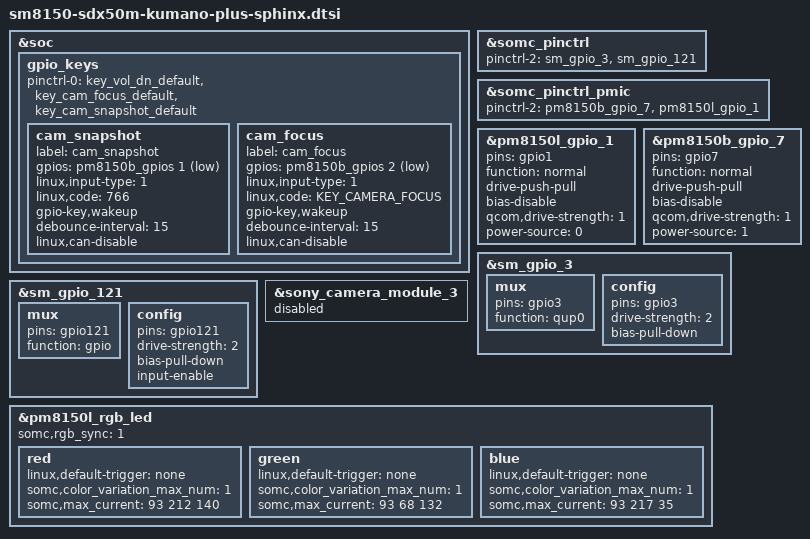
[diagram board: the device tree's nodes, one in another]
/* arch/arm64/boot/dts/somc/sm8150-sdx50m-kumano-plus-sphinx.dtsi
 *
 * This program is free software; you can redistribute it and/or modify
 * it under the terms of the GNU General Public License version 2 and
 * only version 2 as published by the Free Software Foundation.
 *
 * This program is distributed in the hope that it will be useful,
 * but WITHOUT ANY WARRANTY; without even the implied warranty of
 * MERCHANTABILITY or FITNESS FOR A PARTICULAR PURPOSE.  See the
 * GNU General Public License for more details.
 */

#include "sm8150-sdx50m-kumano-plus-common.dtsi"

&soc {
	gpio_keys {
		pinctrl-0 = <&key_vol_dn_default
			     &key_cam_focus_default
			     &key_cam_snapshot_default>;

		cam_snapshot {
			label = "cam_snapshot";
			gpios = <&pm8150b_gpios 1 GPIO_ACTIVE_LOW>;
			linux,input-type = <1>;
			linux,code = <766>;
			gpio-key,wakeup;
			debounce-interval = <15>;
			linux,can-disable;
		};

		cam_focus {
			label = "cam_focus";
			gpios = <&pm8150b_gpios 2 GPIO_ACTIVE_LOW>;
			linux,input-type = <1>;
			linux,code = <KEY_CAMERA_FOCUS>;
			gpio-key,wakeup;
			debounce-interval = <15>;
			linux,can-disable;
		};
	};
};

&somc_pinctrl {
	/* If variant specific default setting is needed,
	fill pinctrl-2 value in <variant>.dtsi */
	pinctrl-2 = <&sm_gpio_3 &sm_gpio_121>;
};

&somc_pinctrl_pmic {
	/* If variant specific PMIC default setting is needed,
	fill pinctrl-2 value in <variant>.dtsi */
	pinctrl-2 = <&pm8150b_gpio_7 &pm8150l_gpio_1>;
};

/* GPIO_1: TS_VDDIO_EN(do not initialize output value) */
&pm8150l_gpio_1 {
	pins = "gpio1";
	function = "normal";
	/delete-property/ output-high;
	drive-push-pull;
	bias-disable;
	qcom,drive-strength = <1>; /* Low */
	power-source = <0>;
};

/* GPIO_7: TS_VDDH_EN(do not initialize output value) */
&pm8150b_gpio_7 {
	pins = "gpio7";
	function = "normal";
	/delete-property/ output-low;
	drive-push-pull;
	bias-disable;
	qcom,drive-strength = <1>; /* Low */
	power-source = <1>;
};

/* GPIO_3 : NFC_ESE_SPI_CS_N */
&sm_gpio_3 {
	mux {
		pins = "gpio3";
		function = "qup0";
	};

	config {
		pins = "gpio3";
		drive-strength = <2>;
		/delete-property/bias-disable;
		bias-pull-down;
		/delete-property/output-low;
	};
};

/* GPIO_121 : NC */
&sm_gpio_121 {
	mux {
		pins = "gpio121";
		function = "gpio";
	};

	config {
		pins = "gpio121";
		drive-strength = <2>;
		/delete-property/ bias-disable;
		bias-pull-down;
		input-enable;
	};
};

&sony_camera_module_3 {
	status = "disabled";
};

&pm8150l_rgb_led {
	somc,rgb_sync = <1>;
	red {
		linux,default-trigger = "none";
		somc,color_variation_max_num = <1>;
		somc,max_current = <
			93 212 140>;
	};
	green {
		linux,default-trigger = "none";
		somc,color_variation_max_num = <1>;
		somc,max_current = <
			93 68 132>;
	};
	blue {
		linux,default-trigger = "none";
		somc,color_variation_max_num = <1>;
		somc,max_current = <
			93 217 35>;
	};
};

#include "sec_touchscreen.dtsi"
#include "somc-kumano-touch_sphinx.dtsi"
#include "somc-kumano-display.dtsi"
#include "somc-kumano-plus-display-sphinx.dtsi"
#include "charger-kumano-common.dtsi"
#include "charger-kumano-plus-sphinx.dtsi"
#include "somc-kumano-nfc_pn557.dtsi"
#include "somc-kumano-sensor_adux1050.dtsi"
